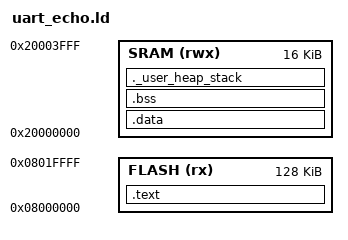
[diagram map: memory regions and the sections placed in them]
/******************************************************************************
 *
 * uart_echo.ld - Linker configuration file for uart_echo.
 *
 * Copyright (c) 2013-2014 Texas Instruments Incorporated.  All rights reserved.
 * Software License Agreement
 * 
 * Texas Instruments (TI) is supplying this software for use solely and
 * exclusively on TI's microcontroller products. The software is owned by
 * TI and/or its suppliers, and is protected under applicable copyright
 * laws. You may not combine this software with "viral" open-source
 * software in order to form a larger program.
 * 
 * THIS SOFTWARE IS PROVIDED "AS IS" AND WITH ALL FAULTS.
 * NO WARRANTIES, WHETHER EXPRESS, IMPLIED OR STATUTORY, INCLUDING, BUT
 * NOT LIMITED TO, IMPLIED WARRANTIES OF MERCHANTABILITY AND FITNESS FOR
 * A PARTICULAR PURPOSE APPLY TO THIS SOFTWARE. TI SHALL NOT, UNDER ANY
 * CIRCUMSTANCES, BE LIABLE FOR SPECIAL, INCIDENTAL, OR CONSEQUENTIAL
 * DAMAGES, FOR ANY REASON WHATSOEVER.
 * 
 * This is part of revision 2.1.0.12573 of the EK-TM4C1294XL Firmware Package.
 *
 *****************************************************************************/

MEMORY
{
    FLASH (rx) : ORIGIN = 0x08000000, LENGTH = 0x00020000
    SRAM (rwx) : ORIGIN = 0x20000000, LENGTH = 0x00004000
}
_Min_Heap_Size = 0x200;      /* required amount of heap  */
_Min_Stack_Size = 0x400; /* required amount of stack */
SECTIONS
{
    .text :
    {
        _text = .;
        KEEP(*(.isr_vector))
        *(.text*)
        *(.rodata*)
        _etext = .;
    } > FLASH

    .data : AT(ADDR(.text) + SIZEOF(.text))
    {
        _data = .;
        *(vtable)
        *(.data*)
        _edata = .;
    } > SRAM

    .bss :
    {
        _bss = .;
        *(.bss*)
        *(COMMON)
        _ebss = .;
    } > SRAM
	  /* User_heap_stack section, used to check that there is enough RAM left */
  ._user_heap_stack :
  {
    . = ALIGN(4);
    PROVIDE ( end = . );
    PROVIDE ( _end = . );
    . = . + _Min_Heap_Size;
    . = . + _Min_Stack_Size;
    . = ALIGN(4);
  } >SRAM

  __cs3_heap_end = .; /* for _sbrk */
}
